# PY32F003xx register map
Vendor: Puya; Series: PY32F0; File version: 1.0.0
CPU: CM0+ r0p1, little endian, no MPU, no FPU, 4 interrupt priority bits
Registers are 32-bit, read-write, reset 0x0 unless marked. A register's access mark holds for its fields unless they carry their own. Offsets are from the block's base; [hi:lo] are bit positions; {n}, {i} and the like mark numbered series; 'fields as' and 'values as' point back to an identical list.

## TIM1 — Advanced timer
Base 0x40012C00
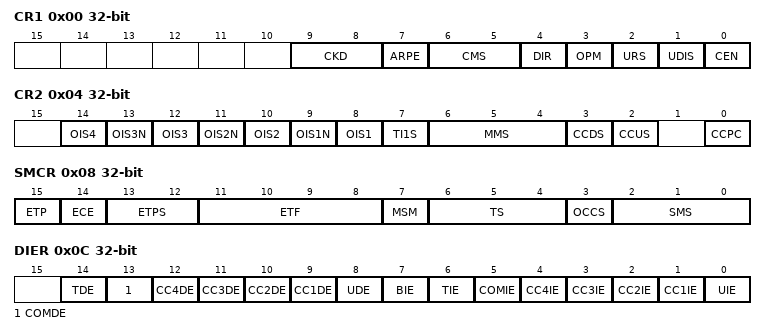
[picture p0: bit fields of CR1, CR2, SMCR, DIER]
0x00 CR1 — control register 1
  [9:8] CKD — Clock division
    0=Div1 (t_DTS = t_CK_INT); 1=Div2 (t_DTS = 2 x t_CK_INT); 2=Div4 (t_DTS = 4 x t_CK_INT)
  [7] ARPE — Auto-reload preload enable
    0=Disabled (TIMx_APRR register is not buffered); 1=Enabled (TIMx_APRR register is buffered)
  [6:5] CMS — Center-aligned mode selection
    0=EdgeAligned (The counter counts up or down depending on the direction bit); 1=CenterAligned1 (The counter counts up and down alternatively. Output compare interrupt flags are set only when the counter is counting down.); 2=CenterAligned2 (The counter counts up and down alternatively. Output compare interrupt flags are set only when the counter is counting up.); 3=CenterAligned3 (The counter counts up and down alternatively. Output compare interrupt flags are set both when the counter is counting up or down.)
  [4] DIR — Direction
    0=Up (Counter used as upcounter); 1=Down (Counter used as downcounter)
  [3] OPM — One-pulse mode
    0=Disabled (Counter is not stopped at update event); 1=Enabled (Counter stops counting at the next update event (clearing the CEN bit))
  [2] URS — Update request source
    0=AnyEvent (Any of counter overflow/underflow, setting UG, or update through slave mode, generates an update interrupt or DMA request); 1=CounterOnly (Only counter overflow/underflow generates an update interrupt or DMA request)
  [1] UDIS — Update disable
    0=Enabled (Update event enabled); 1=Disabled (Update event disabled)
  [0] CEN — Counter enable
    0=Disabled (Counter disabled); 1=Enabled (Counter enabled)
0x04 CR2 — control register 2
  [2n+6] OIS{n} (n=1..4) — Output Idle state {n}
  [13] OIS3N — Output Idle state 3
  [11] OIS2N — Output Idle state 2
  [9] OIS1N — Output Idle state 1
  [7] TI1S — TI1 selection
    0=Normal (The TIMx_CH1 pin is connected to TI1 input); 1=XOR (The TIMx_CH1, CH2, CH3 pins are connected to TI1 input)
  [6:4] MMS — Master mode selection
    0=Reset (The UG bit from the TIMx_EGR register is used as trigger output); 1=Enable (The counter enable signal, CNT_EN, is used as trigger output); 2=Update (The update event is selected as trigger output); 3=ComparePulse (The trigger output send a positive pulse when the CC1IF flag it to be set, as soon as a capture or a compare match occurred); {v}=CompareOC{v-3} (OC{v-3}REF signal is used as trigger output) (v=4..7)
  [3] CCDS — Capture/compare DMA selection
    0=OnCompare (CCx DMA request sent when CCx event occurs); 1=OnUpdate (CCx DMA request sent when update event occurs)
  [2] CCUS — Capture/compare control update selection
    0=Bit (When capture/compare control bits are preloaded (CCPC=1), they are updated by setting the COMG bit only); 1=BitOrEdge (When capture/compare control bits are preloaded (CCPC=1), they are updated by setting the COMG bit or when an rising edge occurs on TRGI)
  [0] CCPC — Capture/compare preloaded control
0x08 SMCR — slave mode control register
  [15] ETP — External trigger polarity
    0=NotInverted (ETR is noninverted, active at high level or rising edge); 1=Inverted (ETR is inverted, active at low level or falling edge)
  [14] ECE — External clock enable
    0=Disabled (External clock mode 2 disabled); 1=Enabled (External clock mode 2 enabled. The counter is clocked by any active edge on the ETRF signal.)
  [13:12] ETPS — External trigger prescaler
    0=Div1 (Prescaler OFF); 1=Div2 (ETRP frequency divided by 2); 2=Div4 (ETRP frequency divided by 4); 3=Div8 (ETRP frequency divided by 8)
  [11:8] ETF — External trigger filter
    0=No filter, sampling is done at fDTS; 1=FCK_INT_N2 (fSAMPLING=fCK_INT, N=2); 2=FCK_INT_N4 (fSAMPLING=fCK_INT, N=4); 3=FCK_INT_N8 (fSAMPLING=fCK_INT, N=8); 4=FDTS_Div2_N6 (fSAMPLING=fDTS/2, N=6); 5=FDTS_Div2_N8 (fSAMPLING=fDTS/2, N=8); 6=FDTS_Div4_N6 (fSAMPLING=fDTS/4, N=6); 7=FDTS_Div4_N8 (fSAMPLING=fDTS/4, N=8); 8=FDTS_Div8_N6 (fSAMPLING=fDTS/8, N=6); 9=FDTS_Div8_N8 (fSAMPLING=fDTS/8, N=8); 10=FDTS_Div16_N5 (fSAMPLING=fDTS/16, N=5); 11=FDTS_Div16_N6 (fSAMPLING=fDTS/16, N=6); 12=FDTS_Div16_N8 (fSAMPLING=fDTS/16, N=8); 13=FDTS_Div32_N5 (fSAMPLING=fDTS/32, N=5); 14=FDTS_Div32_N6 (fSAMPLING=fDTS/32, N=6); 15=FDTS_Div32_N8 (fSAMPLING=fDTS/32, N=8)
  [7] MSM — Master/Slave mode
    0=NoSync (No action); 1=Sync (The effect of an event on the trigger input (TRGI) is delayed to allow a perfect synchronization between the current timer and its slaves (through TRGO). It is useful if we want to synchronize several timers on a single external event.)
  [6:4] TS — Trigger selection
    0=ITR0 (Internal Trigger 0 (ITR0)); 1=ITR1 (Internal Trigger 1 (ITR1)); 2=ITR2 (Internal Trigger 2 (ITR2)); 4=TI1F_ED (TI1 Edge Detector (TI1F_ED)); 5=TI1FP1 (Filtered Timer Input 1 (TI1FP1)); 6=TI2FP2 (Filtered Timer Input 2 (TI2FP2)); 7=ETRF (External Trigger input (ETRF))
  [3] OCCS — OCREF clear selection bit
  [2:0] SMS — Slave mode selection
    0=Disabled (Slave mode disabled - if CEN = ‘1 then the prescaler is clocked directly by the internal clock.); 1=Encoder mode 1 - Counter counts up/down on TI2FP1 edge depending on TI1FP2 level; 2=Encoder mode 2 - Counter counts up/down on TI1FP2 edge depending on TI2FP1 level; 3=Encoder mode 3 - Counter counts up/down on both TI1FP1 and TI2FP2 edges depending on the level of the other input; 4=Reset Mode - Rising edge of the selected trigger input (TRGI) reinitializes the counter and generates an update of the registers; 5=Gated Mode - The counter clock is enabled when the trigger input (TRGI) is high. The counter stops (but is not reset) as soon as the trigger becomes low. Both start and stop of the counter are controlled.; 6=Trigger Mode - The counter starts at a rising edge of the trigger TRGI (but it is not reset). Only the start of the counter is controlled.; 7=Ext_Clock_Mode (External Clock Mode 1 - Rising edges of the selected trigger (TRGI) clock the counter.)
0x0C DIER — DMA/Interrupt enable register
  [14] TDE — Trigger DMA request enable
    0=Disabled (Trigger DMA request disabled); 1=Enabled (Trigger DMA request enabled)
  [13] COMDE — COM DMA request enable
  [n+8] CC{n}DE (n=1..4) — Capture/Compare {n} DMA request enable
    0=Disabled (CCx DMA request disabled); 1=Enabled (CCx DMA request enabled)
  [8] UDE — Update DMA request enable
    0=Disabled (Update DMA request disabled); 1=Enabled (Update DMA request enabled)
  [7] BIE — Break interrupt enable
  [6] TIE — Trigger interrupt enable
    0=Disabled (Trigger interrupt disabled); 1=Enabled (Trigger interrupt enabled)
  [5] COMIE — COM interrupt enable
  [n] CC{n}IE (n=1..4) — Capture/Compare {n} interrupt enable
    0=Disabled (CCx interrupt disabled); 1=Enabled (CCx interrupt enabled)
  [0] UIE — Update interrupt enable
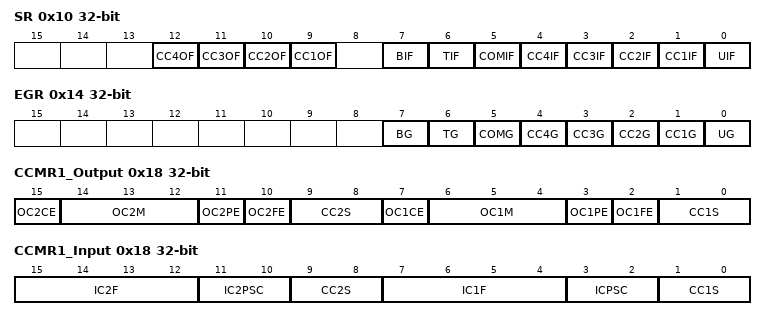
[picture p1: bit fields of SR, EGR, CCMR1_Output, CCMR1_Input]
0x10 SR — status register
  [12] CC4OF write-0-clears — Capture/Compare 4 overcapture flag
    on read: 1=Overcapture (The counter value has been captured in TIMx_CCRx register while CCxIF flag was already set) | on write: 0=Clear flag
  [11] CC3OF write-0-clears — Capture/Compare 3 overcapture flag
    values as CC4OF
  [10] CC2OF write-0-clears — Capture/compare 2 overcapture flag
    values as CC4OF
  [9] CC1OF write-0-clears — Capture/Compare 1 overcapture flag
    values as CC4OF
  [7] BIF — Break interrupt flag
  [6] TIF write-0-clears — Trigger interrupt flag
    on read: 0=No trigger event occurred; 1=Trigger interrupt pending | on write: 0=Clear flag
  [5] COMIF — COM interrupt flag
  [4] CC4IF write-0-clears — Capture/Compare 4 interrupt flag
    on read: 1=Match (If CC1 is an output: The content of the counter TIMx_CNT matches the content of the TIMx_CCR1 register. If CC1 is an input: The counter value has been captured in TIMx_CCR1 register.) | on write: 0=Clear flag
  [3] CC3IF write-0-clears — Capture/Compare 3 interrupt flag
    values as CC4IF
  [2] CC2IF write-0-clears — Capture/Compare 2 interrupt flag
    values as CC4IF
  [1] CC1IF write-0-clears — Capture/compare 1 interrupt flag
    values as CC4IF
  [0] UIF — Update interrupt flag
0x14 EGR wo — event generation register
  [7] BG — Break generation
  [6] TG — Trigger generation
    1=Trigger (The TIF flag is set in TIMx_SR register. Related interrupt or DMA transfer can occur if enabled.)
  [5] COMG — Capture/Compare control update generation
  [n] CC{n}G (n=1..4) — Capture/compare {n} generation
    1=Trigger (If CC1 is an output: CC1IF flag is set, Corresponding interrupt or DMA request is sent if enabled. If CC1 is an input: The current value of the counter is captured in TIMx_CCR1 register.)
  [0] UG — Update generation
    1=Trigger (Re-initializes the timer counter and generates an update of the registers.)
0x18 CCMR1_Output — capture/compare mode register (output mode)
  [15] OC2CE — Output Compare 2 clear enable
  [14:12] OC2M — Output Compare 2 mode
    0=Frozen (The comparison between the output compare register TIMx_CCRy and the counter TIMx_CNT has no effect on the outputs / OpmMode1: Retriggerable OPM mode 1 - In up-counting mode, the channel is active until a trigger event is detected (on TRGI signal). In down-counting mode, the channel is inactive); 1=ActiveOnMatch (Set channel to active level on match. OCyREF signal is forced high when the counter matches the capture/compare register / OpmMode2: Inversely to OpmMode1); 2=InactiveOnMatch (Set channel to inactive level on match. OCyREF signal is forced low when the counter matches the capture/compare register / Reserved); 3=Toggle (OCyREF toggles when TIMx_CNT=TIMx_CCRy / Reserved); 4=ForceInactive (OCyREF is forced low / CombinedPwmMode1: OCyREF has the same behavior as in PWM mode 1. OCyREFC is the logical OR between OC1REF and OC2REF); 5=ForceActive (OCyREF is forced high / CombinedPwmMode2: OCyREF has the same behavior as in PWM mode 2. OCyREFC is the logical AND between OC1REF and OC2REF); 6=PwmMode1 (In upcounting, channel is active as long as TIMx_CNT<TIMx_CCRy else inactive. In downcounting, channel is inactive as long as TIMx_CNT>TIMx_CCRy else active / AsymmetricPwmMode1: OCyREF has the same behavior as in PWM mode 1. OCyREFC outputs OC1REF when the counter is counting up, OC2REF when it is counting down); 7=PwmMode2 (Inversely to PwmMode1 / AsymmetricPwmMode2: Inversely to AsymmetricPwmMode1)
  [11] OC2PE — Output Compare 2 preload enable
    0=Disabled (Preload register on CCR2 disabled. New values written to CCR2 are taken into account immediately); 1=Enabled (Preload register on CCR2 enabled. Preload value is loaded into active register on each update event)
  [10] OC2FE — Output Compare 2 fast enable
  [9:8] CC2S — Capture/Compare 2 selection
    0=Output (CC2 channel is configured as output)
  [7] OC1CE — Output Compare 1 clear enable
  [6:4] OC1M — Output Compare 1 mode
    values as OC2M
  [3] OC1PE — Output Compare 1 preload enable
    0=Disabled (Preload register on CCR1 disabled. New values written to CCR1 are taken into account immediately); 1=Enabled (Preload register on CCR1 enabled. Preload value is loaded into active register on each update event)
  [2] OC1FE — Output Compare 1 fast enable
  [1:0] CC1S — Capture/Compare 1 selection
    0=Output (CC1 channel is configured as output)
0x18 CCMR1_Input (alternate view of CCMR1_Output) — capture/compare mode register 1 (input mode)
  [15:12] IC2F — Input capture 2 filter
  [11:10] IC2PSC — Input capture 2 prescaler
  [9:8] CC2S — Capture/Compare 2 selection
    1=TI2 (CC2 channel is configured as input, IC2 is mapped on TI2); 2=TI1 (CC2 channel is configured as input, IC2 is mapped on TI1); 3=TRC (CC2 channel is configured as input, IC2 is mapped on TRC)
  [7:4] IC1F — Input capture 1 filter
    values as SMCR.ETF
  [3:2] ICPSC — Input capture 1 prescaler
  [1:0] CC1S — Capture/Compare 1 selection
    1=TI1 (CC1 channel is configured as input, IC1 is mapped on TI1); 2=TI2 (CC1 channel is configured as input, IC1 is mapped on TI2); 3=TRC (CC1 channel is configured as input, IC1 is mapped on TRC)
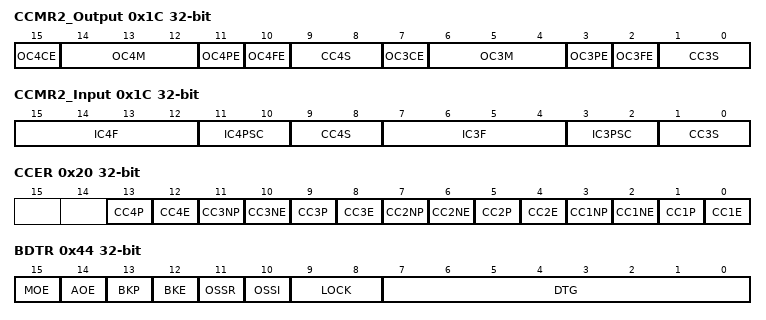
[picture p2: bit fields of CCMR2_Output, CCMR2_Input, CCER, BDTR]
0x1C CCMR2_Output — capture/compare mode register (output mode)
  [15] OC4CE — Output compare 4 clear enable
  [14:12] OC4M — Output compare 4 mode
    values as CCMR1_Output.OC2M
  [11] OC4PE — Output compare 4 preload enable
    0=Disabled (Preload register on CCRx disabled. New values written to CCRx are taken into account immediately); 1=Enabled (Preload register on CCRx enabled. Preload value is loaded into active register on each update event)
  [10] OC4FE — Output compare 4 fast enable
  [9:8] CC4S — Capture/Compare 4 selection
    0=Output (CCx channel is configured as output)
  [7] OC3CE — Output compare 3 clear enable
  [6:4] OC3M — Output compare 3 mode
    values as CCMR1_Output.OC2M
  [3] OC3PE — Output compare 3 preload enable
    values as OC4PE
  [2] OC3FE — Output compare 3 fast enable
  [1:0] CC3S — Capture/Compare 3 selection
    0=Output (CCx channel is configured as output)
0x1C CCMR2_Input (alternate view of CCMR2_Output) — capture/compare mode register 2 (input mode)
  [15:12] IC4F — Input capture 4 filter
  [11:10] IC4PSC — Input capture 4 prescaler
  [9:8] CC4S — Capture/Compare 4 selection
    0=Output (CC4 channel is configured as output); 1=TI4 (CC4 channel is configured as input, IC4 is mapped on TI4); 2=TI3 (CC4 channel is configured as input, IC4 is mapped on TI3); 3=TRC (CC4 channel is configured as input, IC4 is mapped on TRC)
  [7:4] IC3F — Input capture 3 filter
  [3:2] IC3PSC — Input capture 3 prescaler
  [1:0] CC3S — Capture/compare 3 selection
    0=Output (CC3 channel is configured as output); 1=TI3 (CC3 channel is configured as input, IC3 is mapped on TI3); 2=TI4 (CC3 channel is configured as input, IC3 is mapped on TI4); 3=TRC (CC3 channel is configured as input, IC3 is mapped on TRC)
0x20 CCER — capture/compare enable register
  [13] CC4P — Capture/Compare 3 output Polarity
  [4n-4] CC{n}E (n=1..4) — Capture/Compare {n} output enable
  [11] CC3NP — Capture/Compare 3 output Polarity
  [10] CC3NE — Capture/Compare 3 complementary output enable
  [9] CC3P — Capture/Compare 3 output Polarity
  [7] CC2NP — Capture/Compare 2 output Polarity
  [6] CC2NE — Capture/Compare 2 complementary output enable
  [5] CC2P — Capture/Compare 2 output Polarity
  [3] CC1NP — Capture/Compare 1 output Polarity
  [2] CC1NE — Capture/Compare 1 complementary output enable
  [1] CC1P — Capture/Compare 1 output Polarity
0x24 CNT — counter
  [15:0] CNT — counter value
0x28 PSC — prescaler
  [15:0] PSC — Prescaler value
0x2C ARR — auto-reload register
  [15:0] ARR — Auto-reload value
0x30 RCR — repetition counter register
  [7:0] REP — Repetition counter value
{0x30+4i} CCR{i} (i=1..4) — capture/compare register {i}
  [15:0] CCR1 — Capture/Compare 1 value
0x44 BDTR — break and dead-time register
  [15] MOE — Main output enable
  [14] AOE — Automatic output enable
  [13] BKP — Break polarity
  [12] BKE — Break enable
  [11] OSSR — Off-state selection for Run mode
  [10] OSSI — Off-state selection for Idle mode
  [9:8] LOCK — Lock configuration
  [7:0] DTG — Dead-time generator setup
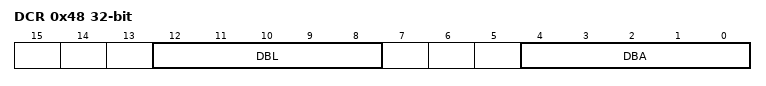
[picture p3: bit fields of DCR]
0x48 DCR — DMA control register
  [12:8] DBL range 0..18 — DMA burst length
  [4:0] DBA — DMA base address
0x4C DMAR — DMA address for full transfer
  [15:0] DMAB — DMA register for burst accesses
